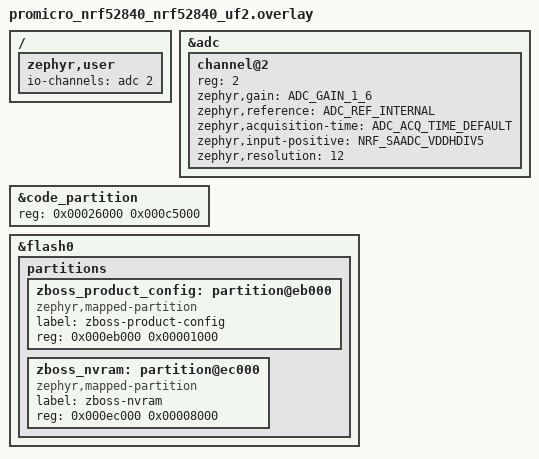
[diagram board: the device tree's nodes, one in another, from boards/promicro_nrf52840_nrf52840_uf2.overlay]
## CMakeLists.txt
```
cmake_minimum_required(VERSION 3.20.0)
set(ZEPHYR_EXTRA_MODULES "C:/ncs/ncs-zigbee")
find_package(Zephyr REQUIRED HINTS $ENV{ZEPHYR_BASE})
project(zigbutton_v6)
target_sources(app PRIVATE src/main.c src/toggle.c)
```

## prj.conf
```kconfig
CONFIG_GPIO=y
CONFIG_ADC=y

CONFIG_ZIGBEE_ADD_ON=y
CONFIG_ZIGBEE_APP_UTILS=y
CONFIG_ZIGBEE_ROLE_END_DEVICE=y

CONFIG_ZIGBEE_CHANNEL_SELECTION_MODE_SINGLE=y
CONFIG_ZIGBEE_CHANNEL=11

CONFIG_HEAP_MEM_POOL_SIZE=2048
CONFIG_SYSTEM_WORKQUEUE_STACK_SIZE=2048

CONFIG_RAM_POWER_DOWN_LIBRARY=y
CONFIG_PM_DEVICE=n

CONFIG_WATCHDOG=n

CONFIG_SERIAL=n
CONFIG_CONSOLE=n
CONFIG_UART_CONSOLE=n
CONFIG_LOG=n
CONFIG_SHELL=n

CONFIG_USB_DEVICE_STACK=n
CONFIG_USB_DEVICE_STACK_NEXT=n

CONFIG_DK_LIBRARY=n
```

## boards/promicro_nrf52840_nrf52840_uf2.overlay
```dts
/*
 * ZigButtonDIY
 *
 * Mémoire nice!nano / Pro Micro nRF52840 UF2 :
 *
 * 0x000000 - 0x026000 : SoftDevice S140
 * 0x026000 - 0x0EB000 : Application
 * 0x0EB000 - 0x0EC000 : ZBOSS Product Config
 * 0x0EC000 - 0x0F4000 : ZBOSS NVRAM
 * 0x0F4000 - 0x100000 : UF2 Bootloader
 *
 * Batterie :
 *
 * mesure directe de VDDH via l'entrée interne
 * SAADC VDDHDIV5.
 *
 * Aucun GPIO externe n'est utilisé pour
 * la mesure batterie.
 */

#include <zephyr/dt-bindings/adc/nrf-saadc.h>

/ {
    zephyr,user {
        io-channels = <&adc 2>;
    };
};

&adc {
    status = "okay";

    #address-cells = <1>;
    #size-cells = <0>;

    channel@2 {
        reg = <2>;

        /*
         * Référence interne 0,6 V
         * Gain 1/6
         */
        zephyr,gain = "ADC_GAIN_1_6";
        zephyr,reference = "ADC_REF_INTERNAL";
        zephyr,acquisition-time = <ADC_ACQ_TIME_DEFAULT>;

        /*
         * Mesure interne :
         *
         * VDDH / 5
         */
        zephyr,input-positive = <NRF_SAADC_VDDHDIV5>;

        zephyr,resolution = <12>;
    };
};


/*
 * ---------------------------------------------------------
 * MEMOIRE
 * ---------------------------------------------------------
 *
 * NE PAS TOUCHER AUX 48 Kio DU BOOTLOADER UF2.
 */

&code_partition {
    reg = <0x00026000 0x000c5000>;
};


/delete-node/ &storage_partition;


&flash0 {
    partitions {

        zboss_product_config: partition@eb000 {
            compatible = "zephyr,mapped-partition";
            label = "zboss-product-config";
            reg = <0x000eb000 0x00001000>;
        };

        zboss_nvram: partition@ec000 {
            compatible = "zephyr,mapped-partition";
            label = "zboss-nvram";
            reg = <0x000ec000 0x00008000>;
        };
    };
};
```

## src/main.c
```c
#include "battery_curve.h"
#include "toggle.h"
#include <zephyr/kernel.h>
#include <zephyr/device.h>
#include <zephyr/drivers/gpio.h>
#include <zephyr/drivers/adc.h>
#include <zephyr/sys/util.h>

#include <ram_pwrdn.h>

#include <zboss_api.h>
#include <zboss_api_addons.h>
#include <zboss_api_zcl.h>

#include <zcl/zb_zcl_power_config.h>
#include <ha/zb_ha_dimmer_switch.h>

#include <zigbee/zigbee_app_utils.h>
#include <zb_nrf_platform.h>

#define BUTTON_PIN       17
#define SWITCH_ENDPOINT  1
#define DEBOUNCE_TIME_MS 35

#include "battery_config.h"
#define BATTERY_ADC_MULTIPLIER 5
#define BATTERY_REPORT_INTERVAL_HOURS 4

static const struct device *gpio0 =
    DEVICE_DT_GET(DT_NODELABEL(gpio0));

static struct gpio_callback button_gpio_cb;
static struct k_work_delayable debounce_work;

static int last_button_state;
static struct k_work_delayable battery_work;
static bool boot_report_sent;

volatile uint32_t battery_adc_errors, battery_schedule_errors;
volatile uint32_t zigbee_buffer_errors;
volatile int battery_last_mv;

static const struct adc_dt_spec battery_adc =
    ADC_DT_SPEC_GET_BY_IDX(
        DT_PATH(zephyr_user),
        0
    );

struct zigbutton_device_ctx
{
    zb_zcl_basic_attrs_t basic_attr;
    zb_zcl_identify_attrs_t identify_attr;

    zb_uint8_t battery_voltage;

    zb_uint8_t battery_percentage_remaining;
};

static struct zigbutton_device_ctx dev_ctx;

ZB_ZCL_DECLARE_BASIC_SERVER_ATTRIB_LIST(
    basic_attr_list,
    &dev_ctx.basic_attr.zcl_version,
    &dev_ctx.basic_attr.power_source
);

ZB_ZCL_DECLARE_IDENTIFY_SERVER_ATTRIB_LIST(
    identify_attr_list,
    &dev_ctx.identify_attr.identify_time
);

ZB_ZCL_START_DECLARE_ATTRIB_LIST_CLUSTER_REVISION(
    power_config_attr_list,
    ZB_ZCL_POWER_CONFIG
)

    ZB_SET_ATTR_DESCR_WITH_ZB_ZCL_ATTR_POWER_CONFIG_BATTERY_VOLTAGE_ID(
        &dev_ctx.battery_voltage,
    ),

    ZB_SET_ATTR_DESCR_WITH_ZB_ZCL_ATTR_POWER_CONFIG_BATTERY_PERCENTAGE_REMAINING_ID(
        &dev_ctx.battery_percentage_remaining,
    ),

ZB_ZCL_FINISH_DECLARE_ATTRIB_LIST;

static zb_zcl_cluster_desc_t zigbutton_clusters[] =
{
    ZB_ZCL_CLUSTER_DESC(
        ZB_ZCL_CLUSTER_ID_BASIC,
        ZB_ZCL_ARRAY_SIZE(
            basic_attr_list,
            zb_zcl_attr_t
        ),
        basic_attr_list,
        ZB_ZCL_CLUSTER_SERVER_ROLE,
        ZB_ZCL_MANUF_CODE_INVALID
    ),

    ZB_ZCL_CLUSTER_DESC(
        ZB_ZCL_CLUSTER_ID_IDENTIFY,
        ZB_ZCL_ARRAY_SIZE(
            identify_attr_list,
            zb_zcl_attr_t
        ),
        identify_attr_list,
        ZB_ZCL_CLUSTER_SERVER_ROLE,
        ZB_ZCL_MANUF_CODE_INVALID
    ),

    ZB_ZCL_CLUSTER_DESC(
        ZB_ZCL_CLUSTER_ID_POWER_CONFIG,
        ZB_ZCL_ARRAY_SIZE(
            power_config_attr_list,
            zb_zcl_attr_t
        ),
        power_config_attr_list,
        ZB_ZCL_CLUSTER_SERVER_ROLE,
        ZB_ZCL_MANUF_CODE_INVALID
    ),

    ZB_ZCL_CLUSTER_DESC(
        ZB_ZCL_CLUSTER_ID_IDENTIFY,
        0,
        NULL,
        ZB_ZCL_CLUSTER_CLIENT_ROLE,
        ZB_ZCL_MANUF_CODE_INVALID
    ),

    ZB_ZCL_CLUSTER_DESC(
        ZB_ZCL_CLUSTER_ID_SCENES,
        0,
        NULL,
        ZB_ZCL_CLUSTER_CLIENT_ROLE,
        ZB_ZCL_MANUF_CODE_INVALID
    ),

    ZB_ZCL_CLUSTER_DESC(
        ZB_ZCL_CLUSTER_ID_GROUPS,
        0,
        NULL,
        ZB_ZCL_CLUSTER_CLIENT_ROLE,
        ZB_ZCL_MANUF_CODE_INVALID
    ),

    ZB_ZCL_CLUSTER_DESC(
        ZB_ZCL_CLUSTER_ID_ON_OFF,
        0,
        NULL,
        ZB_ZCL_CLUSTER_CLIENT_ROLE,
        ZB_ZCL_MANUF_CODE_INVALID
    ),

    ZB_ZCL_CLUSTER_DESC(
        ZB_ZCL_CLUSTER_ID_LEVEL_CONTROL,
        0,
        NULL,
        ZB_ZCL_CLUSTER_CLIENT_ROLE,
        ZB_ZCL_MANUF_CODE_INVALID
    )
};

ZB_DECLARE_SIMPLE_DESC(3, 5);

ZB_AF_SIMPLE_DESC_TYPE(3, 5)
simple_desc_zigbutton_ep =
{
    SWITCH_ENDPOINT,

    ZB_AF_HA_PROFILE_ID,

    ZB_HA_DIMMER_SWITCH_DEVICE_ID,

    0 ,

    0,

    3,
    5,

    {
        ZB_ZCL_CLUSTER_ID_BASIC,
        ZB_ZCL_CLUSTER_ID_IDENTIFY,
        ZB_ZCL_CLUSTER_ID_POWER_CONFIG,

        ZB_ZCL_CLUSTER_ID_ON_OFF,
        ZB_ZCL_CLUSTER_ID_LEVEL_CONTROL,
        ZB_ZCL_CLUSTER_ID_SCENES,
        ZB_ZCL_CLUSTER_ID_GROUPS,
        ZB_ZCL_CLUSTER_ID_IDENTIFY,
    }
};

ZB_AF_DECLARE_ENDPOINT_DESC(
    zigbutton_ep,

    SWITCH_ENDPOINT,

    ZB_AF_HA_PROFILE_ID,

    0,
    NULL,

    ZB_ZCL_ARRAY_SIZE(
        zigbutton_clusters,
        zb_zcl_cluster_desc_t
    ),

    zigbutton_clusters,

    (zb_af_simple_desc_1_1_t *)
        &simple_desc_zigbutton_ep,

    0,
    NULL,

    0,
    NULL
);

ZBOSS_DECLARE_DEVICE_CTX_1_EP(
    zigbutton_ctx,
    zigbutton_ep
);

static int battery_adc_init(void)
{
    if (!adc_is_ready_dt(&battery_adc))
    {
        return -ENODEV;
    }

    return adc_channel_setup_dt(
        &battery_adc
    );
}

static int battery_measure_mv(void)
{
    int err;

    int16_t raw;
    int32_t mv;

    struct adc_sequence sequence =
    {
        .buffer = &raw,
        .buffer_size = sizeof(raw),
    };

    err =
        adc_sequence_init_dt(
            &battery_adc,
            &sequence
        );

    if (err != 0)
    {
        return err;
    }

    err =
        adc_read(
            battery_adc.dev,
            &sequence
        );

    if (err != 0)
    {
        return err;
    }

    mv = raw;

    err =
        adc_raw_to_millivolts_dt(
            &battery_adc,
            &mv
        );

    if (err != 0)
    {
        return err;
    }

    mv *= BATTERY_ADC_MULTIPLIER;
    
    mv = (int32_t)(((int64_t)mv * BATTERY_CAL_GAIN_NUM +
                   BATTERY_CAL_GAIN_DEN / 2) / BATTERY_CAL_GAIN_DEN)
         + BATTERY_CAL_OFFSET_MV;
    battery_last_mv = mv;

    return (int)mv;
}

static bool battery_measure_zigbee_values(
    zb_uint8_t *battery_voltage,
    zb_uint8_t *battery_percentage_remaining)
{
    int mv =
        battery_measure_mv();

    if (mv <= 0)
    {
        *battery_voltage =
            ZB_ZCL_POWER_CONFIG_BATTERY_VOLTAGE_INVALID;

        *battery_percentage_remaining =
            ZB_ZCL_POWER_CONFIG_BATTERY_REMAINING_UNKNOWN;

        return false;
    }

    int voltage_zigbee =
        (mv + 50) / 100;

    if (voltage_zigbee > 254)
    {
        voltage_zigbee = 254;
    }

    *battery_voltage =
        (zb_uint8_t)voltage_zigbee;

    uint8_t percent =
        battery_percent_from_mv(
            mv
        );

    *battery_percentage_remaining =
        (zb_uint8_t)(
            percent * 2
        );

    return true;
}

volatile uint32_t battery_report_confirmed, battery_report_failed;
static void battery_sent(zb_bufid_t bufid)
{
    zb_zcl_command_send_status_t *status = ZB_BUF_GET_PARAM(bufid, zb_zcl_command_send_status_t);
    if (status->status == RET_OK) { battery_report_confirmed++; }
    else { battery_report_failed++; }
    zb_buf_free(bufid);
}

static void send_battery_report(
    zb_bufid_t bufid)
{
    zb_uint16_t destination =
        0x0000;

    zb_uint8_t *ptr;

    if (!ZB_JOINED())
    {
        zb_buf_free(
            bufid
        );

        return;
    }

    ptr =
        ZB_ZCL_START_PACKET(
            bufid
        );

    ZB_ZCL_CONSTRUCT_GENERAL_COMMAND_REQ_FRAME_CONTROL_EXT(
        ptr,

        ZB_ZCL_NOT_MANUFACTURER_SPECIFIC,

        ZB_ZCL_FRAME_DIRECTION_TO_CLI,

        ZB_ZCL_DISABLE_DEFAULT_RESPONSE
    );

    ZB_ZCL_CONSTRUCT_COMMAND_HEADER(
        ptr,

        ZB_ZCL_GET_SEQ_NUM(),

        ZB_ZCL_CMD_REPORT_ATTRIB
    );

    ZB_ZCL_PACKET_PUT_DATA16_VAL(
        ptr,

        ZB_ZCL_ATTR_POWER_CONFIG_BATTERY_VOLTAGE_ID
    );

    ZB_ZCL_PACKET_PUT_DATA8(
        ptr,

        ZB_ZCL_ATTR_TYPE_U8
    );

    ZB_ZCL_PACKET_PUT_DATA8(
        ptr,

        dev_ctx.battery_voltage
    );

    ZB_ZCL_PACKET_PUT_DATA16_VAL(
        ptr,

        ZB_ZCL_ATTR_POWER_CONFIG_BATTERY_PERCENTAGE_REMAINING_ID
    );

    ZB_ZCL_PACKET_PUT_DATA8(
        ptr,

        ZB_ZCL_ATTR_TYPE_U8
    );

    ZB_ZCL_PACKET_PUT_DATA8(
        ptr,

        dev_ctx.battery_percentage_remaining
    );

    zb_addr_u address = {0};
    address.addr_short = destination;
    zb_ret_t result = zb_zcl_finish_and_send_packet(bufid, ptr, &address,
        ZB_APS_ADDR_MODE_16_ENDP_PRESENT, 1, SWITCH_ENDPOINT,
        ZB_AF_HA_PROFILE_ID, ZB_ZCL_CLUSTER_ID_POWER_CONFIG, battery_sent);
    if (result != RET_OK) {
        battery_report_failed++;
        zb_buf_free(bufid);
    }
}

static void battery_update_zigbee(zb_uint8_t valid, zb_uint16_t packed)
{
    ARG_UNUSED(valid);
    dev_ctx.battery_voltage = (zb_uint8_t)(packed >> 8);
    dev_ctx.battery_percentage_remaining = (zb_uint8_t)packed;
    if (ZB_JOINED() && zb_buf_get_out_delayed(send_battery_report) != RET_OK) {
        zigbee_buffer_errors++;
    }
}

static void battery_periodic_handler(struct k_work *work)
{
    ARG_UNUSED(work);
    zb_uint8_t voltage, percentage;
    bool valid = battery_measure_zigbee_values(&voltage, &percentage);
    if (!valid) { battery_adc_errors++; }
    zb_uint16_t packed = ((zb_uint16_t)voltage << 8) | percentage;
    if (ZB_SCHEDULE_APP_CALLBACK2(battery_update_zigbee, valid, packed) != RET_OK) {
        battery_schedule_errors++;
    }
    k_work_reschedule(&battery_work, K_HOURS(BATTERY_REPORT_INTERVAL_HOURS));
}

static void debounce_handler(struct k_work *work)
{
    ARG_UNUSED(work);
    int state = gpio_pin_get(gpio0, BUTTON_PIN);
    if (state < 0 || state == last_button_state) { return; }
    last_button_state = state;
    toggle_enqueue();
}

static void button_interrupt(
    const struct device *dev,

    struct gpio_callback *cb,

    uint32_t pins)
{
    ARG_UNUSED(dev);
    ARG_UNUSED(cb);
    ARG_UNUSED(pins);

    k_work_reschedule(
        &debounce_work,

        K_MSEC(
            DEBOUNCE_TIME_MS
        )
    );
}

static int button_init(void)
{
    int err;

    if (!device_is_ready(gpio0))
    {
        return -ENODEV;
    }

    err =
        gpio_pin_configure(
            gpio0,

            BUTTON_PIN,

            GPIO_INPUT |
            GPIO_PULL_UP
        );

    if (err != 0)
    {
        return err;
    }

    last_button_state =
        gpio_pin_get(
            gpio0,
            BUTTON_PIN
        );

    k_work_init_delayable(
        &debounce_work,

        debounce_handler
    );

    gpio_init_callback(
        &button_gpio_cb,

        button_interrupt,

        BIT(BUTTON_PIN)
    );

    err =
        gpio_add_callback(
            gpio0,

            &button_gpio_cb
        );

    if (err != 0)
    {
        return err;
    }

    if (last_button_state < 0) { return last_button_state; }
    return gpio_pin_interrupt_configure(
        gpio0,

        BUTTON_PIN,

        GPIO_INT_EDGE_BOTH
    );
}

static void zigbee_attributes_init(void)
{
    dev_ctx.basic_attr.zcl_version =
        ZB_ZCL_VERSION;

    dev_ctx.basic_attr.power_source =
        ZB_ZCL_BASIC_POWER_SOURCE_BATTERY;

    dev_ctx.identify_attr.identify_time =
        ZB_ZCL_IDENTIFY_IDENTIFY_TIME_DEFAULT_VALUE;

    dev_ctx.battery_voltage =
        ZB_ZCL_POWER_CONFIG_BATTERY_VOLTAGE_INVALID;

    dev_ctx.battery_percentage_remaining =
        ZB_ZCL_POWER_CONFIG_BATTERY_REMAINING_UNKNOWN;

    (void)battery_measure_zigbee_values(
        &dev_ctx.battery_voltage,
        &dev_ctx.battery_percentage_remaining
    );
}

void zboss_signal_handler(zb_bufid_t bufid)
{
    zb_zdo_app_signal_type_t signal = zb_get_app_signal(bufid, NULL);
    if (signal == ZB_ZDO_SIGNAL_SKIP_STARTUP ||
        ((signal == ZB_BDB_SIGNAL_DEVICE_FIRST_START || signal == ZB_BDB_SIGNAL_DEVICE_REBOOT) &&
         ZB_GET_APP_SIGNAL_STATUS(bufid) == RET_OK)) {
        zigbee_configure_sleepy_behavior(true);
    }
    (void)zigbee_default_signal_handler(bufid);
    
    if (!boot_report_sent &&
        (signal == ZB_BDB_SIGNAL_STEERING || signal == ZB_BDB_SIGNAL_DEVICE_REBOOT) &&
        ZB_GET_APP_SIGNAL_STATUS(bufid) == RET_OK && ZB_JOINED()) {
        if (zb_buf_get_out_delayed(send_battery_report) == RET_OK) {
            boot_report_sent = true;
        } else {
            zigbee_buffer_errors++;
        }
    }
    if (bufid) { zb_buf_free(bufid); }
}

int main(void)
{
    int err;
    toggle_init();

    err =
        button_init();

    if (err != 0)
    {
        return 0;
    }

    err = battery_adc_init();
    if (err != 0) { battery_adc_errors++; }

    zigbee_attributes_init();

    ZB_AF_REGISTER_DEVICE_CTX(
        &zigbutton_ctx
    );

    zigbee_configure_sleepy_behavior(
        true
    );

    if (
        IS_ENABLED(
            CONFIG_RAM_POWER_DOWN_LIBRARY
        )
    )
    {
        power_down_unused_ram();
    }

    k_work_init_delayable(&battery_work, battery_periodic_handler);
    k_work_schedule(&battery_work, K_HOURS(BATTERY_REPORT_INTERVAL_HOURS));
    zigbee_enable();

    return 0;
}
```

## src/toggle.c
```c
/* All ZBOSS calls run in the Zigbee callback. Queue/flight state is locked.
 * No new application toggle is sent on ambiguous delivery failure. */
#include <zephyr/kernel.h>
#include <zephyr/drivers/gpio.h>
#include <zephyr/sys/atomic.h>
#include <zboss_api.h>
#include <zboss_api_zcl.h>
#include <zigbee/zigbee_app_utils.h>
#include "toggle.h"
#include "toggle_queue.h"
static struct toggle_queue queue;
static struct k_spinlock lock;
static struct k_work_delayable pump_work, led_work;
static atomic_t callback_pending;
static const struct gpio_dt_spec led = GPIO_DT_SPEC_GET(DT_ALIAS(led0), gpios);
static bool led_ready, busy, timed_out;
static int64_t submitted_at;
static unsigned led_edges;
static bool led_on;
volatile uint32_t toggle_enqueued, toggle_overflow, toggle_expired;
volatile uint32_t toggle_no_network, toggle_no_buffer, toggle_schedule_errors;
volatile uint32_t toggle_submitted, toggle_confirmed, toggle_failed, toggle_timeouts;
volatile int toggle_last_status;
static void led_handler(struct k_work *work) {
    ARG_UNUSED(work);
    k_spinlock_key_t key = k_spin_lock(&lock);
    bool again = led_edges > 0;
    if (again) { led_on = !led_on; led_edges--; }
    bool on = led_on;
    k_spin_unlock(&lock, key);
    if (led_ready) gpio_pin_set_dt(&led, on);
    if (again) k_work_reschedule(&led_work, K_MSEC(120));
}
static void feedback(bool success) {
    k_spinlock_key_t key = k_spin_lock(&lock);
    /* One short pulse for stack confirmation; three for failure/uncertainty.
     * Closely spaced events can merge feedback; counters remain separate. */
    led_on = false;
    led_edges = success ? 2 : 6;
    k_spin_unlock(&lock, key);
    k_work_reschedule(&led_work, K_NO_WAIT);
}
static void sent(zb_bufid_t bufid) {
    zb_zcl_command_send_status_t *result = ZB_BUF_GET_PARAM(bufid, zb_zcl_command_send_status_t);
    int status = result->status;
    zb_buf_free(bufid);
    k_spinlock_key_t key = k_spin_lock(&lock);
    bool was_timeout = timed_out;
    busy = false;
    toggle_last_status = status;
    if (status == RET_OK) toggle_confirmed++; else toggle_failed++;
    k_spin_unlock(&lock, key);
    if (!was_timeout) feedback(status == RET_OK);
    k_work_reschedule(&pump_work, K_NO_WAIT);
}
static void pump_zigbee(zb_uint8_t unused, zb_uint16_t unused2) {
    ARG_UNUSED(unused); ARG_UNUSED(unused2);
    k_spinlock_key_t key = k_spin_lock(&lock);
    unsigned expired = tq_expire(&queue, k_uptime_get());
    toggle_expired += expired;
    bool eligible = queue.count && !busy;
    k_spin_unlock(&lock, key);
    if (expired) feedback(false);
    if (!eligible) goto done;
    user_input_indicate();
    if (!ZB_JOINED()) {
        key = k_spin_lock(&lock); tq_pop(&queue); toggle_no_network++; k_spin_unlock(&lock,key);
        feedback(false); goto done;
    }
    zb_bufid_t bufid = zb_buf_get_out();
    if (!bufid) { toggle_no_buffer++; goto done; }
    key = k_spin_lock(&lock);
    /* Workqueue can expire the queue while the buffer is being allocated. */
    expired = tq_expire(&queue, k_uptime_get()); toggle_expired += expired;
    eligible = queue.count != 0;
    if (eligible) { tq_pop(&queue); busy = true; timed_out = false; submitted_at = k_uptime_get(); toggle_submitted++; }
    k_spin_unlock(&lock, key);
    if (expired) feedback(false);
    if (!eligible) { zb_buf_free(bufid); goto done; }
    zb_uint8_t *ptr = zb_zcl_start_command_header(bufid,
        ZB_ZCL_CONSTRUCT_FRAME_CONTROL(ZB_ZCL_FRAME_TYPE_CLUSTER_SPECIFIC,
            ZB_ZCL_NOT_MANUFACTURER_SPECIFIC, ZB_ZCL_FRAME_DIRECTION_TO_SRV,
            ZB_ZCL_DISABLE_DEFAULT_RESPONSE), 0, ZB_ZCL_CMD_ON_OFF_TOGGLE_ID, NULL);
    zb_addr_u destination = {0};
    /* Standard unicast with AUTO security and APS ACK enabled in this SDK.
     * Callback owns the buffer on RET_OK, including asynchronous abort. */
    zb_ret_t rc = zb_zcl_finish_and_send_packet(bufid, ptr, &destination,
        ZB_APS_ADDR_MODE_16_ENDP_PRESENT, 1, 1, ZB_AF_HA_PROFILE_ID,
        ZB_ZCL_CLUSTER_ID_ON_OFF, sent);
    if (rc != RET_OK) {
        zb_buf_free(bufid);
        key = k_spin_lock(&lock); busy = false; toggle_failed++; toggle_last_status = rc; k_spin_unlock(&lock,key);
        feedback(false);
    }
done:
    atomic_clear(&callback_pending);
    k_work_reschedule(&pump_work, K_MSEC(100));
}
static void pump_handler(struct k_work *work) {
    ARG_UNUSED(work);
    int64_t now = k_uptime_get();
    k_spinlock_key_t key = k_spin_lock(&lock);
    unsigned expired = tq_expire(&queue, now); toggle_expired += expired;
    bool timeout = busy && !timed_out && now - submitted_at >= 15000;
    if (timeout) { timed_out = true; toggle_timeouts++; }
    bool pending = queue.count != 0;
    bool flight = busy && !timed_out;
    int64_t remaining = flight ? 15000 - (now - submitted_at) : 0;
    k_spin_unlock(&lock,key);
    if (expired || timeout) feedback(false);
    if (pending && atomic_cas(&callback_pending, 0, 1)) {
        if (ZB_SCHEDULE_APP_CALLBACK2(pump_zigbee,0,0) != RET_OK) {
            atomic_clear(&callback_pending); toggle_schedule_errors++;
        }
    }
    if (pending) k_work_schedule(&pump_work,K_MSEC(100));
    else if (flight) k_work_schedule(&pump_work,K_MSEC(MAX(remaining,1)));
    /* If a callback never returns, do not free its buffer or send another
     * toggle. Report uncertainty once. A late callback safely unblocks us. */
}
void toggle_enqueue(void) {
    k_spinlock_key_t key = k_spin_lock(&lock);
    bool ok = tq_push(&queue,k_uptime_get());
    if (ok) toggle_enqueued++; else toggle_overflow++;
    k_spin_unlock(&lock,key);
    if (!ok) feedback(false);
    k_work_reschedule(&pump_work,K_NO_WAIT);
}
void toggle_init(void) {
    k_work_init_delayable(&pump_work,pump_handler);
    k_work_init_delayable(&led_work,led_handler);
    led_ready = gpio_is_ready_dt(&led) && gpio_pin_configure_dt(&led,GPIO_OUTPUT_INACTIVE) == 0;
}
```

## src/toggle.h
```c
#pragma once
void toggle_init(void);
void toggle_enqueue(void);
```
